# HT32F52342_52 register map
File version: 1.0
CPU: CM0+ r0p1, little endian, no MPU, no FPU, 4 interrupt priority bits
Registers are 32-bit, read-write, reset 0x0 unless marked. A register's access mark holds for its fields unless they carry their own. Offsets are from the block's base; [hi:lo] are bit positions; {n}, {i} and the like mark numbered series.

## PWRCU
Base 0x4006A100
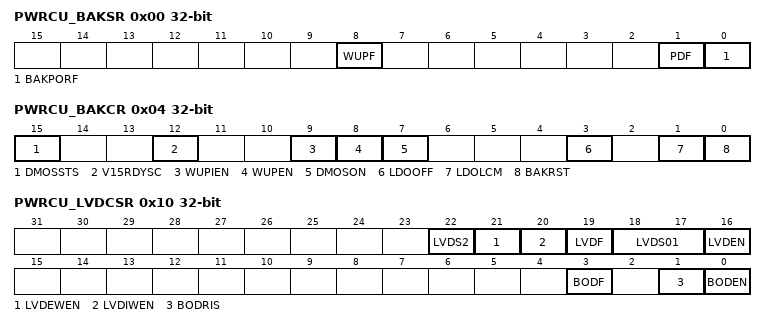
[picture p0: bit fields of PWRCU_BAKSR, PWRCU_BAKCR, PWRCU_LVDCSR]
0x00 PWRCU_BAKSR
  [8] WUPF, [1] PDF, [0] BAKPORF
0x04 PWRCU_BAKCR
  [15] DMOSSTS, [12] V15RDYSC, [9] WUPIEN, [8] WUPEN, [7] DMOSON, [3] LDOOFF, [1] LDOLCM, [0] BAKRST
0x08 PWRCU_BAKTEST
  [7:0] BAKTEST
0x10 PWRCU_LVDCSR
  [22] LVDS2, [21] LVDEWEN, [20] LVDIWEN, [19] LVDF, [18:17] LVDS01, [16] LVDEN, [3] BODF, [1] BODRIS, [0] BODEN
{0x100+4i} PWRCU_BAKREG{i} (i=0..9)
  [31:0] BAKREG

## CKCU
Base 0x40088000
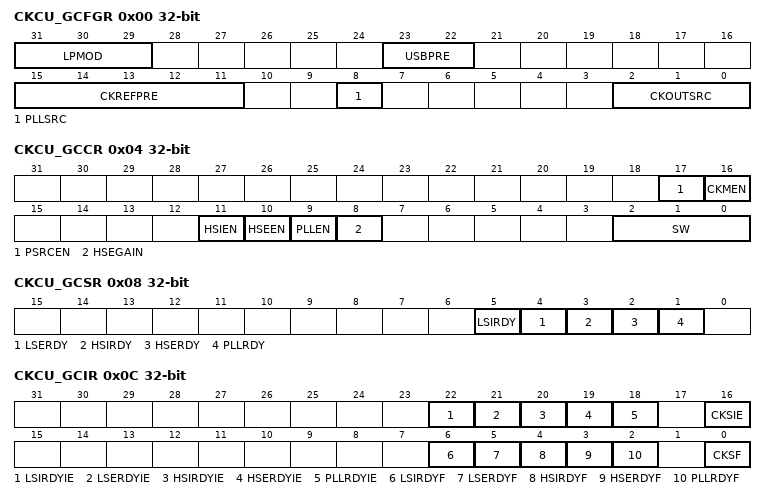
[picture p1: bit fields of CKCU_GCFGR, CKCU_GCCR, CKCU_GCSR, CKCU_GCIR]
0x00 CKCU_GCFGR
  [31:29] LPMOD, [23:22] USBPRE, [15:11] CKREFPRE, [8] PLLSRC, [2:0] CKOUTSRC
0x04 CKCU_GCCR
  [17] PSRCEN, [16] CKMEN, [11] HSIEN, [10] HSEEN, [9] PLLEN, [8] HSEGAIN, [2:0] SW
0x08 CKCU_GCSR
  [5] LSIRDY, [4] LSERDY, [3] HSIRDY, [2] HSERDY, [1] PLLRDY
0x0C CKCU_GCIR
  [22] LSIRDYIE, [21] LSERDYIE, [20] HSIRDYIE, [19] HSERDYIE, [18] PLLRDYIE, [16] CKSIE, [6] LSIRDYF, [5] LSERDYF, [4] HSIRDYF, [3] HSERDYF, [2] PLLRDYF, [0] CKSF
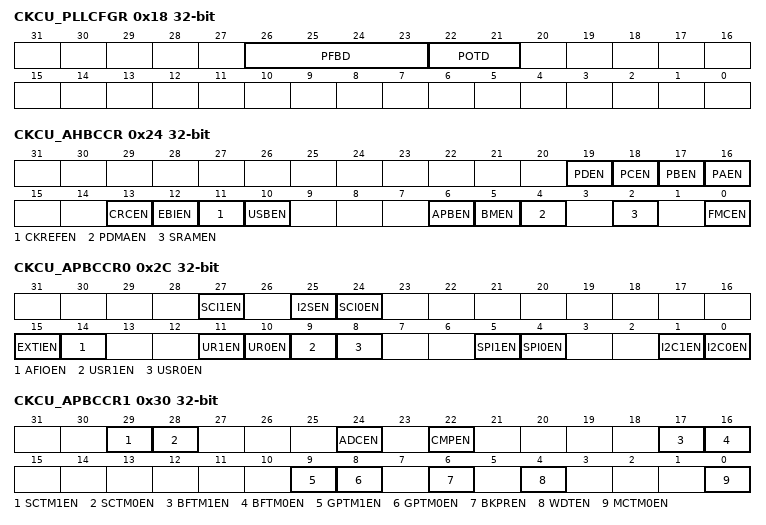
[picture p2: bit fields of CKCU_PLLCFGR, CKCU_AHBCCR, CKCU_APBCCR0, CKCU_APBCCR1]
0x18 CKCU_PLLCFGR
  [26:23] PFBD, [22:21] POTD
0x1C CKCU_PLLCR
  [31] PLLBPS
0x20 CKCU_AHBCFGR
  [2:0] AHBPRE
0x24 CKCU_AHBCCR
  [19] PDEN, [18] PCEN, [17] PBEN, [16] PAEN, [13] CRCEN, [12] EBIEN, [11] CKREFEN, [10] USBEN, [6] APBEN, [5] BMEN, [4] PDMAEN, [2] SRAMEN, [0] FMCEN
0x28 CKCU_APBCFGR
  [18:16] ADCDIV
0x2C CKCU_APBCCR0
  [27] SCI1EN, [25] I2SEN, [24] SCI0EN, [15] EXTIEN, [14] AFIOEN, [11] UR1EN, [10] UR0EN, [9] USR1EN, [8] USR0EN, [5] SPI1EN, [4] SPI0EN, [1] I2C1EN, [0] I2C0EN
0x30 CKCU_APBCCR1
  [29] SCTM1EN, [28] SCTM0EN, [24] ADCEN, [22] CMPEN, [17] BFTM1EN, [16] BFTM0EN, [9] GPTM1EN, [8] GPTM0EN, [6] BKPREN, [4] WDTEN, [0] MCTM0EN
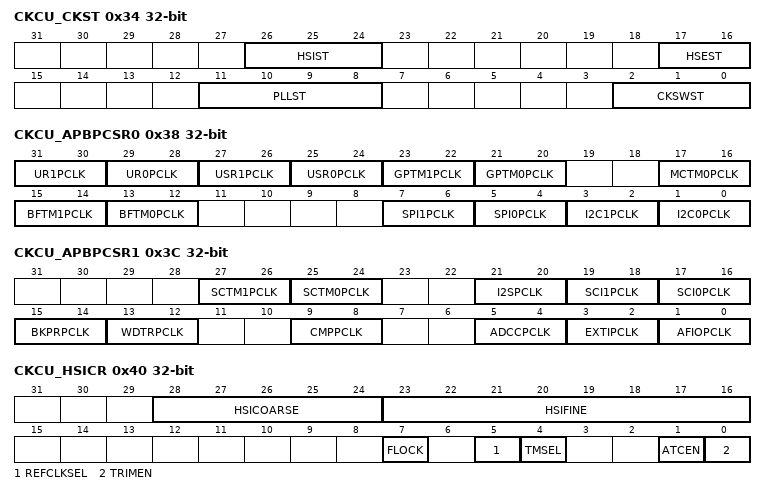
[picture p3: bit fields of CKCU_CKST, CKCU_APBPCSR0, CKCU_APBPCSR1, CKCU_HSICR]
0x34 CKCU_CKST
  [26:24] HSIST, [17:16] HSEST, [11:8] PLLST, [2:0] CKSWST
0x38 CKCU_APBPCSR0
  [31:30] UR1PCLK, [29:28] UR0PCLK, [27:26] USR1PCLK, [25:24] USR0PCLK, [23:22] GPTM1PCLK, [21:20] GPTM0PCLK, [17:16] MCTM0PCLK, [15:14] BFTM1PCLK, [13:12] BFTM0PCLK, [7:6] SPI1PCLK, [5:4] SPI0PCLK, [3:2] I2C1PCLK, [1:0] I2C0PCLK
0x3C CKCU_APBPCSR1
  [27:26] SCTM1PCLK, [25:24] SCTM0PCLK, [21:20] I2SPCLK, [19:18] SCI1PCLK, [17:16] SCI0PCLK, [15:14] BKPRPCLK, [13:12] WDTRPCLK, [9:8] CMPPCLK, [5:4] ADCCPCLK, [3:2] EXTIPCLK, [1:0] AFIOPCLK
0x40 CKCU_HSICR
  [28:24] HSICOARSE, [23:16] HSIFINE, [7] FLOCK, [5] REFCLKSEL, [4] TMSEL, [1] ATCEN, [0] TRIMEN
0x44 CKCU_HSIATCR
  [13:0] ATCNT
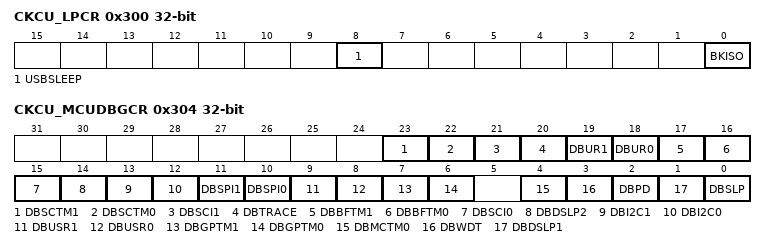
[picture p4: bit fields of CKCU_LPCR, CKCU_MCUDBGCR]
0x300 CKCU_LPCR
  [8] USBSLEEP, [0] BKISO
0x304 CKCU_MCUDBGCR
  [23] DBSCTM1, [22] DBSCTM0, [21] DBSCI1, [20] DBTRACE, [19] DBUR1, [18] DBUR0, [17] DBBFTM1, [16] DBBFTM0, [15] DBSCI0, [14] DBDSLP2, [13] DBI2C1, [12] DBI2C0, [11] DBSPI1, [10] DBSPI0, [9] DBUSR1, [8] DBUSR0, [7] DBGPTM1, [6] DBGPTM0, [4] DBMCTM0, [3] DBWDT, [2] DBPD, [1] DBDSLP1, [0] DBSLP

## RSTCU
Base 0x40088100
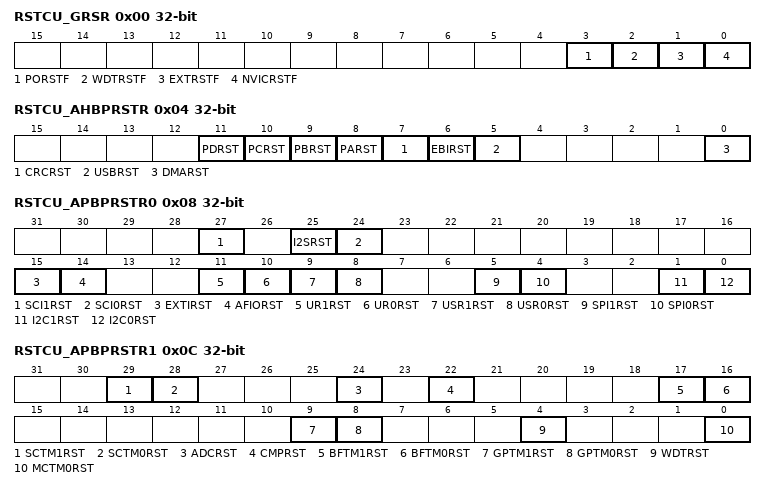
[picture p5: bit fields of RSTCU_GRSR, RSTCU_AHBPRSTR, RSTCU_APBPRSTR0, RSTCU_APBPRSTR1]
0x00 RSTCU_GRSR
  [3] PORSTF, [2] WDTRSTF, [1] EXTRSTF, [0] NVICRSTF
0x04 RSTCU_AHBPRSTR
  [11] PDRST, [10] PCRST, [9] PBRST, [8] PARST, [7] CRCRST, [6] EBIRST, [5] USBRST, [0] DMARST
0x08 RSTCU_APBPRSTR0
  [27] SCI1RST, [25] I2SRST, [24] SCI0RST, [15] EXTIRST, [14] AFIORST, [11] UR1RST, [10] UR0RST, [9] USR1RST, [8] USR0RST, [5] SPI1RST, [4] SPI0RST, [1] I2C1RST, [0] I2C0RST
0x0C RSTCU_APBPRSTR1
  [29] SCTM1RST, [28] SCTM0RST, [24] ADCRST, [22] CMPRST, [17] BFTM1RST, [16] BFTM0RST, [9] GPTM1RST, [8] GPTM0RST, [4] WDTRST, [0] MCTM0RST

## GPIOA
Base 0x400B0000
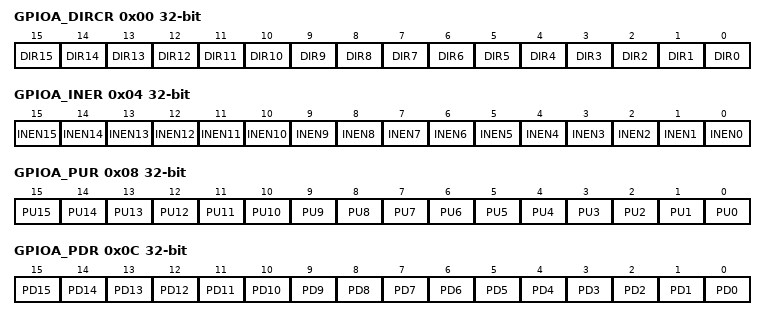
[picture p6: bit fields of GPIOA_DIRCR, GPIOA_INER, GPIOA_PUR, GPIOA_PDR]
0x00 GPIOA_DIRCR
  [n] DIR{n} (n=0..15)
0x04 GPIOA_INER
  [n] INEN{n} (n=0..15)
0x08 GPIOA_PUR
  [n] PU{n} (n=0..15)
0x0C GPIOA_PDR
  [n] PD{n} (n=0..15)
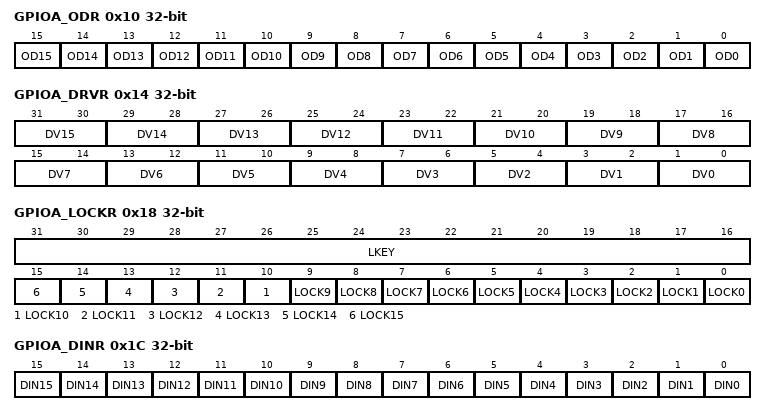
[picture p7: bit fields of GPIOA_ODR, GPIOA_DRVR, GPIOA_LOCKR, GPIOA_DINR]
0x10 GPIOA_ODR
  [n] OD{n} (n=0..15)
0x14 GPIOA_DRVR
  [2n+1:2n] DV{n} (n=0..15)
0x18 GPIOA_LOCKR
  [31:16] LKEY, [n] LOCK{n} (n=0..15)
0x1C GPIOA_DINR
  [n] DIN{n} (n=0..15)
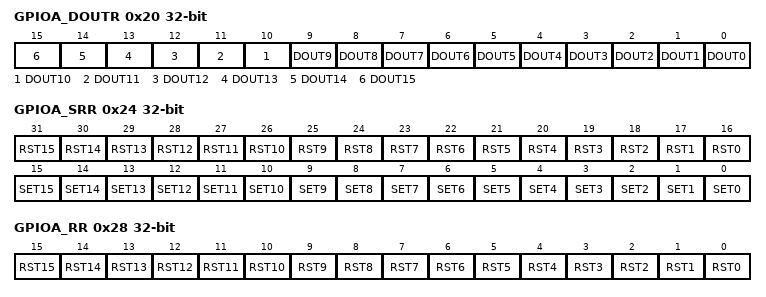
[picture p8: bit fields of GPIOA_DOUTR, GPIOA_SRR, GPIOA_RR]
0x20 GPIOA_DOUTR
  [n] DOUT{n} (n=0..15)
0x24 GPIOA_SRR
  [n+16] RST{n} (n=0..15), [n] SET{n} (n=0..15)
0x28 GPIOA_RR
  [n] RST{n} (n=0..15)

## GPIOB
Base 0x400B2000
Registers as GPIOA (with GPIOA read as GPIOB); these are added or differ:
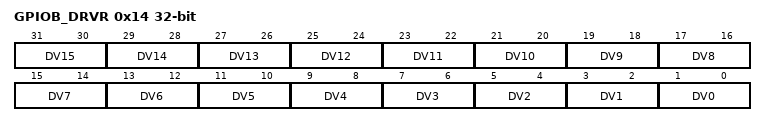
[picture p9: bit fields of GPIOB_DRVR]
0x14 GPIOB_DRVR
  [31:30] DV15
  [29:28] DV14
  [27:26] DV13 — DV11
  [25:24] DV12 — DV11
  [2n+1:2n] DV{n} (n=0..11)

## GPIOC
Base 0x400B4000
Registers as GPIOA (with GPIOA read as GPIOC).

## GPIOD
Base 0x400B6000
Registers as GPIOA (with GPIOA read as GPIOD); these are added or differ:
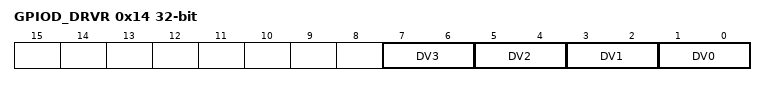
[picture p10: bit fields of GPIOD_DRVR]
0x14 GPIOD_DRVR
  [2n+1:2n] DV{n} (n=0..3)
